# haltium_application register map
Vendor: Nordic Semiconductor; Series: nRFHaltium; File version: 1
CPU: CM33 r0p4, little endian, MPU, FPU, 3 interrupt priority bits, 480 interrupts
Registers are 32-bit, read-write, reset 0x0 unless marked. A register's access mark holds for its fields unless they carry their own. Offsets are from the block's base; [hi:lo] are bit positions; lines under a group give offsets from that group; {n}, {i} and the like mark numbered series; 'fields as' and 'values as' point back to an identical list.

## CACHE0DATA_S — CACHEDATA 0
Base 0xE0F00000
Same registers: CACHE1DATA_S 0xE0F04000
{0x0+0x40*i} SET[{i}] (i=0..255) group — Unspecified
  {0x0+0x20*j} WAY[{j}] (j=0..1) group — Unspecified
    {0x0+8k} DU[{k}] (k=0..3) group — Unspecified
      {0x0+4l} DATA[{l}] (l=0..1) — Description collection: Cache data bits for DATA[q] in DU[p] (DataUnit) of SET[n], WAY[o].
        [31:0] Data

## CACHE0INFO_S — CACHEINFO 0
Base 0xE0F08000
Same registers: CACHE1INFO_S 0xE0F0C000
{0x0+8i} SET[{i}] (i=0..255) group — Unspecified
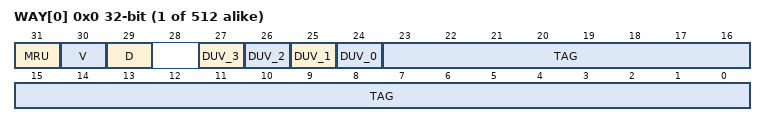
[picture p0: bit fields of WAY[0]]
  {0x0+4j} WAY[{j}] (j=0..1) — Description collection: Cache information for SET[n], WAY[o].
    [31] MRU ro — Most recently used way.
      0=Way0 was most recently used; 1=Way1 was most recently used
    [30] V ro — Line valid bit.
      0=Invalid cache line; 1=Valid cache line
    [29] D ro — Line dirty bit.
      0=Clean cache line; 1=Dirty cache line
    [n+24] DUV_{n} (n=0..3) — Data unit valid info.
      0=Invalid data unit; 1=Valid data unit
    [23:0] TAG — Cache tag.

## RAMC00_NS — RAM Controller 0
Base 0x42004000
Same registers: RAMC00_S 0x52004000
0x100 EVENTS_ERRORFIX — ECC detected fixable (one bit) error in read data from RAM.
  [0] EVENTS_ERRORFIX
    0=NotGenerated (Event not generated); 1=Generated (Event generated)
0x104 EVENTS_ERRORNONFIX — ECC detected non-fixable (multiple bits) error in read data from RAM.
  [0] EVENTS_ERRORNONFIX
    values as EVENTS_ERRORFIX.EVENTS_ERRORFIX
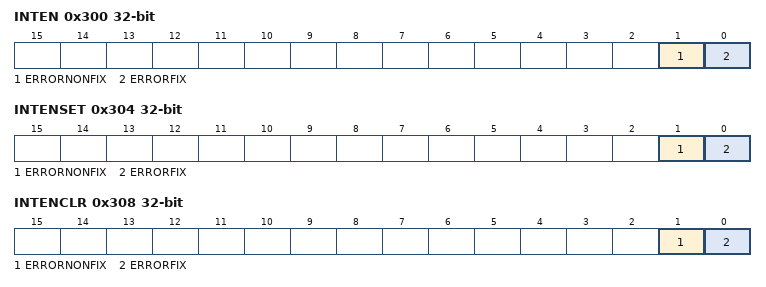
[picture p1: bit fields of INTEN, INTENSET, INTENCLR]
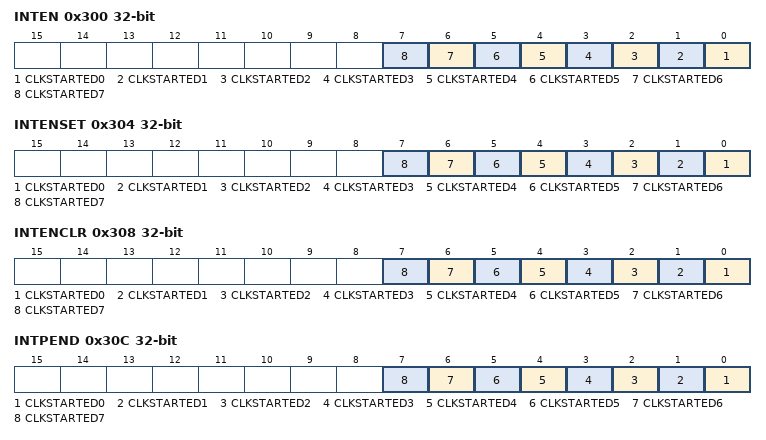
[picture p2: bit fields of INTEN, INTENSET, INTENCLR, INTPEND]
0x300 INTEN — Enable or disable interrupt
  [1] ERRORNONFIX — Enable or disable interrupt for event ERRORNONFIX
    0=Disabled; 1=Enabled
  [0] ERRORFIX — Enable or disable interrupt for event ERRORFIX
    0=Disabled; 1=Enabled
0x304 INTENSET — Enable interrupt
  [1] ERRORNONFIX — Write '1' to enable interrupt for event ERRORNONFIX
    on read: 0=Disabled (Read: Disabled); 1=Enabled (Read: Enabled) | on write: 1=Set (Enable)
  [0] ERRORFIX — Write '1' to enable interrupt for event ERRORFIX
    values as ERRORNONFIX
0x308 INTENCLR — Disable interrupt
  [1] ERRORNONFIX — Write '1' to disable interrupt for event ERRORNONFIX
    on read: 0=Disabled (Read: Disabled); 1=Enabled (Read: Enabled) | on write: 1=Clear (Disable)
  [0] ERRORFIX — Write '1' to disable interrupt for event ERRORFIX
    values as ERRORNONFIX
0x400 FIXADDR ro — Address of the last fixable error detected by the ECC.
  [31:0] ADDR — Address of the last fixable error.
0x404 NONFIXADDR ro — Address of the last non-fixable error detected by the ECC.
  [31:0] ADDR — Address of the last fixable error.
0x500 WAITSTATES — Waitstates for read.
  [2:0] WAITSTATES — Waitstates for read from RAM or ROM.
0x600 SECBASE — Base address for secure access area.
  [31:0] ADDR — Base address
0x604 SECENABLE — Enable secure access restrictions.
  [0] ENABLE — Enable secure access restrictions
    0=Disable (Secure access restrictions disabled); 1=Enable (Secure access restrictions enabled)

## LRC0_S — LRC 0
Base 0x5200E000
Same registers: LRC1_S 0x5201E000
{0x0+4i} TASKS_CLKSTART[{i}] (i=0..7) wo — Description collection: Start the clock source [n]
  [0] TASKS_CLKSTART — Start the clock source [n]
    1=Trigger task
{0x20+4i} TASKS_CLKSTOP[{i}] (i=0..7) wo — Description collection: Clear the TASKS_CLKSTART[n] request
  [0] TASKS_CLKSTOP — Clear the TASKS_CLKSTART[n] request
    1=Trigger task
0x40 TASKS_CONSTLAT wo — Enable constant latency mode
  [0] TASKS_CONSTLAT
    1=Trigger task
0x44 TASKS_LOWPWR wo — Enable Low Power mode
  [0] TASKS_LOWPWR
    1=Trigger task
{0x100+4i} EVENTS_CLKSTARTED[{i}] (i=0..7) — Description collection: Clock [n] started
  [0] EVENTS_CLKSTARTED — Clock [n] started
    0=NotGenerated (Event not generated); 1=Generated (Event generated)
0x300 INTEN — Enable or disable interrupt
  [all] fields
    0=Disabled; 1=Enabled
  [n] CLKSTARTED{n} (n=0..7) — Enable or disable interrupt for event CLKSTARTED[{n}]
0x304 INTENSET — Enable interrupt
  [all] fields
    on read: 0=Disabled (Read: Disabled); 1=Enabled (Read: Enabled) | on write: 1=Set (Enable)
  [n] CLKSTARTED{n} (n=0..7) — Write '1' to enable interrupt for event CLKSTARTED[{n}]
0x308 INTENCLR — Disable interrupt
  [all] fields
    on read: 0=Disabled (Read: Disabled); 1=Enabled (Read: Enabled) | on write: 1=Clear (Disable)
  [n] CLKSTARTED{n} (n=0..7) — Write '1' to disable interrupt for event CLKSTARTED[{n}]
0x30C INTPEND ro — Pending interrupts
  [all] fields
    on read: 0=NotPending (Read: Not pending); 1=Pending (Read: Pending)
  [n] CLKSTARTED{n} (n=0..7) — Read pending status of interrupt for event CLKSTARTED[{n}]
{0x400+8i} CLKSTAT[{i}] (i=0..7) group — Unspecified
  0x00 RUN — Description cluster: Status indicating that TASKS_START task has been triggered for clock [n]
    [0] STATUS — Clock start task triggered or not
      0=NotTriggered (Task not triggered); 1=Triggered (Task triggered)
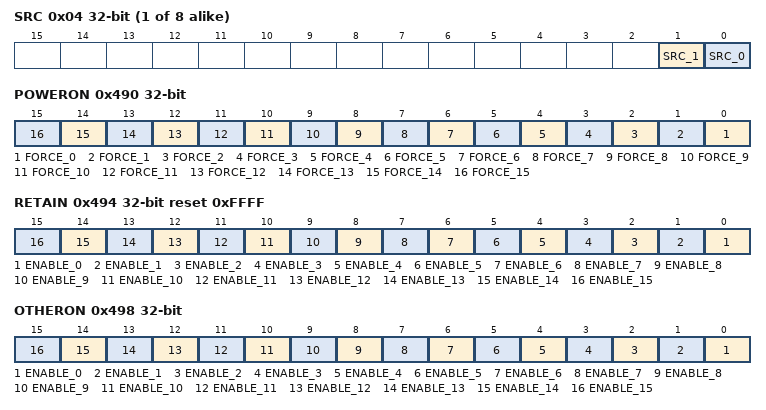
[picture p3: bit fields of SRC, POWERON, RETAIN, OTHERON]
  0x04 SRC — Description cluster: Status indicating which clock source is running for clock [n]
    [1] SRC_1 — Clock source
    [0] SRC_0 — Clock source
{0x440+8i} CLKCTRL[{i}] (i=0..7) group — Unspecified
  0x00 ALWAYSRUN — Description cluster: Force the clock source [n] and tree running always
    [0] FORCE — Force the clock always running
      0=Automatic clock control enabled; 1=AlwaysRun (Clock always running)
  0x04 SRC — Description cluster: Select the clock source for clock [n]
    [1] SRC_1 — Clock source
    [0] SRC_0 — Clock source
0x480 CONSTLATSTAT — Status of constant latency
  [0] STATUS
    0=Low power enabled; 1=ConstLat (Constant latency enabled)
0x490 POWERON — Force power domain ON
  [all] fields
    0=Automatic power control enabled; 1=AlwaysOn (Keep the power domain ON to the domain even though there is no request)
  [n] FORCE_{n} (n=0..15) — Force the power domain ON for domain[{n}]
0x494 RETAIN reset 0xFFFF — Retain power domain
  [all] fields
    0=Disable (Retain disabled); 1=Enable (retain enabled)
  [n] ENABLE_{n} (n=0..15) — Retain the power domain on for domain[{n}]
0x498 OTHERON — Request other domain ON
  [all] fields
    0=Automatic power control enabled; 1=AlwaysOn (Request to keep the other power domain ON to the domain even though there is no request)
  [n] ENABLE_{n} (n=0..15) — Request power domain ON for other domain[{n}]
